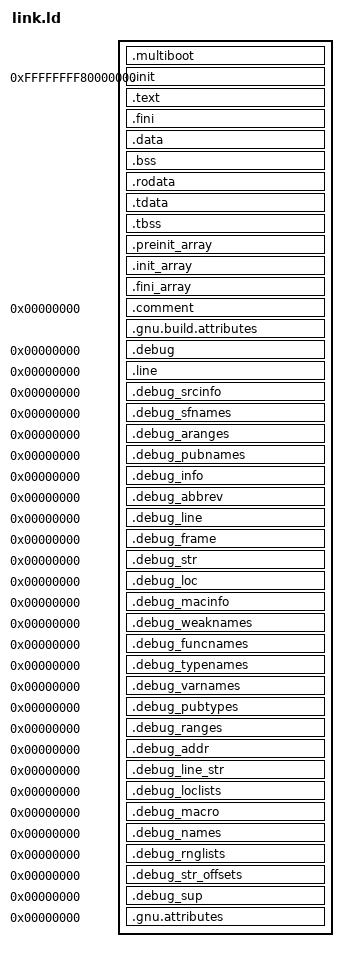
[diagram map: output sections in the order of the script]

OUTPUT_FORMAT(elf64-x86-64)
/* OUTPUT_ARCH(i386:x86-64) */

ENTRY(kernel_entry)

SECTIONS
{
	.multiboot (INFO) :
	{
		*(.multiboot)
	}


	. = 0xFFFFFFFF80000000;

	.init :
	{
		KEEP (*(SORT_NONE(.init)))
	}

	.text :
	{
		*(.text*)
	}

	.fini :
	{
		KEEP (*(SORT_NONE(.fini)))
	}

	.data :
	{
		*(.data*)
	}
	
	.bss :
	{
		*(.bss*)
	}

	.rodata :
	{
		*(.rodata*)
	}

	.tdata :
	{
		*(.tdata*)
	}
	.tbss :
	{
		*(.tbss*)
	}

	.preinit_array :
	{
		PROVIDE_HIDDEN (__preinit_array_start = .);
		KEEP (*(.preinit_array))
		PROVIDE_HIDDEN (__preinit_array_end = .);
	}
	.init_array :
	{
		PROVIDE_HIDDEN (__init_array_start = .);
		KEEP (*(SORT_BY_INIT_PRIORITY(.init_array.*) SORT_BY_INIT_PRIORITY(.ctors.*)))
		KEEP (*(.init_array EXCLUDE_FILE (*crtbegin.o *crtbegin?.o *crtend.o *crtend?.o ) .ctors))
		PROVIDE_HIDDEN (__init_array_end = .);
	}
	.fini_array :
	{
		PROVIDE_HIDDEN (__fini_array_start = .);
		KEEP (*(SORT_BY_INIT_PRIORITY(.fini_array.*) SORT_BY_INIT_PRIORITY(.dtors.*)))
		KEEP (*(.fini_array EXCLUDE_FILE (*crtbegin.o *crtbegin?.o *crtend.o *crtend?.o ) .dtors))
		PROVIDE_HIDDEN (__fini_array_end = .);
	}



	.comment 0 (INFO) : { *(.comment); LINKER_VERSION; }
	.gnu.build.attributes : { *(.gnu.build.attributes .gnu.build.attributes.*) }

	.debug          0 : { *(.debug) }
	.line           0 : { *(.line) }
	.debug_srcinfo  0 : { *(.debug_srcinfo) }
	.debug_sfnames  0 : { *(.debug_sfnames) }
	.debug_aranges  0 : { *(.debug_aranges) }
	.debug_pubnames 0 : { *(.debug_pubnames) }
	.debug_info     0 : { *(.debug_info .gnu.linkonce.wi.*) }
	.debug_abbrev   0 : { *(.debug_abbrev) }
	.debug_line     0 : { *(.debug_line .debug_line.* .debug_line_end) }
	.debug_frame    0 : { *(.debug_frame) }
	.debug_str      0 : { *(.debug_str) }
	.debug_loc      0 : { *(.debug_loc) }
	.debug_macinfo  0 : { *(.debug_macinfo) }
	.debug_weaknames 0 : { *(.debug_weaknames) }
	.debug_funcnames 0 : { *(.debug_funcnames) }
	.debug_typenames 0 : { *(.debug_typenames) }
	.debug_varnames  0 : { *(.debug_varnames) }
	.debug_pubtypes 0 : { *(.debug_pubtypes) }
	.debug_ranges   0 : { *(.debug_ranges) }
	.debug_addr     0 : { *(.debug_addr) }
	.debug_line_str 0 : { *(.debug_line_str) }
	.debug_loclists 0 : { *(.debug_loclists) }
	.debug_macro    0 : { *(.debug_macro) }
	.debug_names    0 : { *(.debug_names) }
	.debug_rnglists 0 : { *(.debug_rnglists) }
	.debug_str_offsets 0 : { *(.debug_str_offsets) }
	.debug_sup      0 : { *(.debug_sup) }
	.gnu.attributes 0 : { KEEP (*(.gnu.attributes)) }

	/DISCARD/ : { *(.note.GNU-stack) *(.gnu_debuglink) *(.gnu.lto_*) }
	
}
